# WKUP_CM register map
Vendor: Texas Instruments
Peripheral module from a debugger description file (folder omap36xx).
Registers are 32-bit, access per field, reset 0x0 unless marked. A register's access mark holds for its fields unless they carry their own. Offsets are as the file gives them; lines under a group give offsets from that group; [hi:lo] are bit positions; {n}, {i} and the like mark numbered series; 'fields as' and 'values as' point back to an identical list; <NAME> marks a mode.

## WKUP_CM
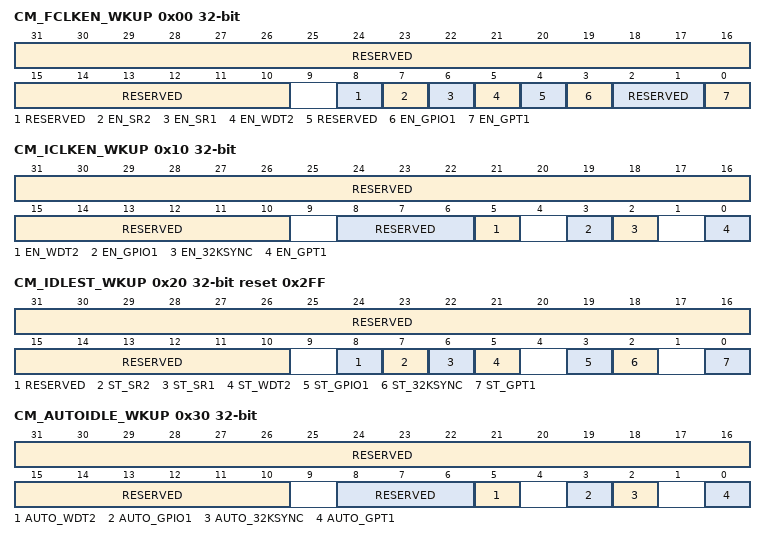
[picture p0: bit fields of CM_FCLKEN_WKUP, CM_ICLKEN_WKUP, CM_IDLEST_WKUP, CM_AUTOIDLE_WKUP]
0x00 CM_FCLKEN_WKUP — Controls the modules functional clock activity.
  [31:10] RESERVED ro — Write 0s for future compatibility. Read returns 0.
  [8] RESERVED ro — Write 0s for future compatibility. Read returns 0.
  [7] EN_SR2 rw — Smart Refex 2 functional clock control.
    0=Smart Reflex 2 functional clock is disabled; 1=Smart Reflex 2 functional clock is enabled
  [6] EN_SR1 rw — Smart Refex 1 functional clock control.
    0=Smart Reflex 1 functional clock is disabled; 1=Smart Reflex 1 functional clock is enabled
  [5] EN_WDT2 rw — WDTIMER 2 functional clock control.
    0=WDTIMER 2 functional clock is disabled; 1=WDTIMER 2 functional clock is enabled
  [4] RESERVED ro — Write 0s for future compatibility. Read returns 0.
  [3] EN_GPIO1 rw — GPIO 1 clock control
    0=GPIO 1 functional clock is disabled; 1=GPIO 1 functional clock is enabled
  [2:1] RESERVED ro — Write 0s for future compatibility. Read returns 0.
  [0] EN_GPT1 rw — GPTIMER 1 clock control
    0=GPTIMER 1 functional clock is disabled; 1=GPTIMER 1 functional clock is enabled
0x10 CM_ICLKEN_WKUP — Controls the modules interface clock activity.
  [31:10] RESERVED ro — Write 0s for future compatibility. Read returns 0.
  [8:6] RESERVED ro — Write 0s for future compatibility. Read returns 0.
  [5] EN_WDT2 rw — WDTIMER 2 interface clock
    0=WDTIMER 2 interface clock is disabled; 1=WDTIMER 2 interface clock is enabled
  [3] EN_GPIO1 rw — GPIO 1 interface clock control
    0=GPIO 1 interface clock is disabled; 1=GPIO 1 interface clock is enabled
  [2] EN_32KSYNC rw — 32 kHz Sync Timer interface clock control
    0=32k Sync Timer interface clock is disabled; 1=32k Sync Timer interface clock is enabled
  [0] EN_GPT1 rw — GPTIMER 1 interface clock control
    0=GPTIMER 1 interface clock is disabled; 1=GPTIMER 1 interface clock is enabled
0x20 CM_IDLEST_WKUP ro reset 0x2FF — WAKEUP domain modules access monitoring.This register is read only and automatically updated.
  [31:10] RESERVED — Read returns 0.
  [8] RESERVED — Read returns 0.
  [7] ST_SR2 — Smart Reflex 2 idle status.
    0=Smart Reflex 2 can be accessed; 1=Smart Reflex 2 cannot be accessed. Any access may return an error.
  [6] ST_SR1 — Smart Reflex 1 idle status.
    0=Smart Reflex 1 can be accessed; 1=Smart Reflex 1 cannot be accessed. Any access may return an error.
  [5] ST_WDT2 — WDTIMER 2 idle status
    0=WDTIMER 2 can be accessed; 1=WDTIMER 2 cannot be accessed. Any access may return an error.
  [3] ST_GPIO1 — GPIO 1 idle status
    0=GPIO 1 can be accessed; 1=GPIO 1 cannot be accessed. Any access may return an error.
  [2] ST_32KSYNC — 32 kHz Sync Timer idle status
    0=32k Sync Timer can be accessed; 1=32k Sync Timer cannot be accessed. Any access may return an error.
  [0] ST_GPT1 — GPTIMER 1 idle status
    0=GPTIMER 1 can be accessed; 1=GPTIMER 1 cannot be accessed. Any access may return an error.
0x30 CM_AUTOIDLE_WKUP — This register controls the automatic control of the WAKEUP modules interface clock activity. This activity is related to CORE domain activity.
  [31:10] RESERVED ro — Write 0s for future compatibility. Read returns 0.
  [8:6] RESERVED ro — Write 0s for future compatibility. Read returns 0.
  [5] AUTO_WDT2 rw — WDTIMER 2 autoidle control
    0=WDTIMER 2 interface clock is unrelated to the domain activity; 1=WDTIMER 2 interface clock is automaticaly enabled or disabled according to the domain activity
  [3] AUTO_GPIO1 rw — GPIO 1 autoidle control
    0=GPIO 1 interface clock is unrelated to the domain activity; 1=GPIO 1 interface clock is automaticaly enabled / disabled according to the domain activity
  [2] AUTO_32KSYNC rw — 32 kHz Sync Timer autoidle control
    0=32k Sync Timer interface clock is unrelated to the domain activity; 1=32k Sync Timer interface clock is automaticaly enabled or disabled according to the domain activity
  [0] AUTO_GPT1 rw — GPTIMER 1 autoidle control
    0=GPTIMER 1 interface clock is unrelated to the domain activity; 1=GPTIMER 1 interface clock is automaticaly enabled or disabled according to the domain activity
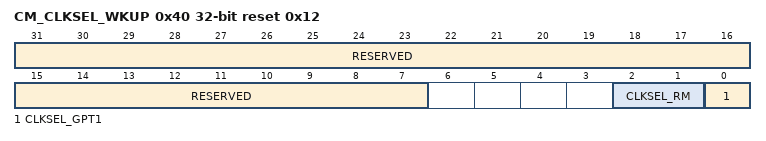
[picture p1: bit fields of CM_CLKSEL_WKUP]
0x40 CM_CLKSEL_WKUP reset 0x12 — WAKEUP domain modules source clock selection.
  [31:7] RESERVED ro — Write 0s for future compatibility. Read returns 0.
  [2:1] CLKSEL_RM rw — Selects the Reset Manager clock; Other enums: Reserved
    1=RM_ICLK is L4_CLK divided by 1; 2=RM_ICLK is L4_CLK divided by 2
  [0] CLKSEL_GPT1 rw — Selects GPTIMER 1 source clock
    0=source is 32K_FCLK; 1=source is SYS_CLK
